# TZ10xx register map
File version: 0.1g
Registers are 32-bit, read-write, reset 0x0 unless marked. A register's access mark holds for its fields unless they carry their own. Offsets are from the block's base; [hi:lo] are bit positions; {n}, {i} and the like mark numbered series; 'fields as' and 'values as' point back to an identical list.

## pmulv (part 1 of 2)
Base 0x40000000
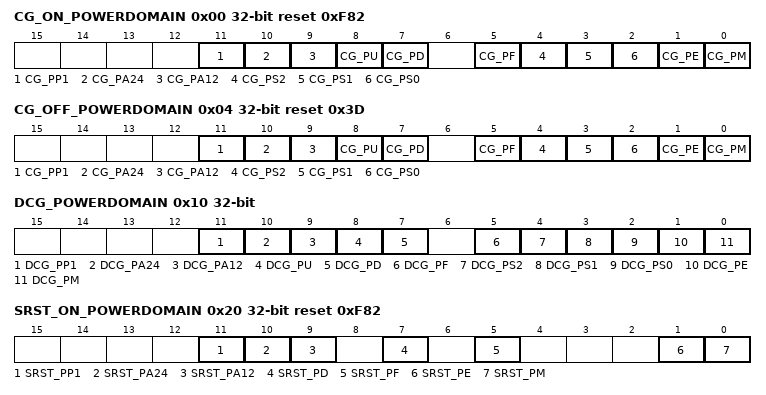
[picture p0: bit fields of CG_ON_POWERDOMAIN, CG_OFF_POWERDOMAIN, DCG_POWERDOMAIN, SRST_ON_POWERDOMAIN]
0x00 CG_ON_POWERDOMAIN reset 0xF82 — Clock gating ON (for each power supply domain) [Write]1: Clock stops. 0: Ignored [Read]1: Clock is stopped. 0: Clock is being supplied. * Writing also changes the values of associated individual CG registers. (Example) If writing is done to the CG_PD field, the values of the [CG_ON_PD] and [CG_OFF_PD] registers are also changed.
  [11] CG_PP1 — Batch control of clocks belonging to PP1
  [10] CG_PA24 — Batch control of clocks belonging to PA24
  [9] CG_PA12 — Batch control of clocks belonging to PA12
  [8] CG_PU — Batch control of clocks belonging to PU
  [7] CG_PD — Batch control of clocks belonging to PD
  [5] CG_PF — Batch control of clocks belonging to PF
  [4] CG_PS2 — Batch control of clocks belonging to PS2
  [3] CG_PS1 — Batch control of clocks belonging to PS1
  [2] CG_PS0 — Batch control of clocks belonging to PS0
  [1] CG_PE — Batch control of clocks belonging to PE
  [0] CG_PM — Batch control of clocks belonging to PM
0x04 CG_OFF_POWERDOMAIN reset 0x3D — Clock gating OFF (for each power supply domain) [Write]1: Clock is supplied. 0: Ignored [Read]1: Clock is being supplied. 0: Clock is stopped. * Writing also changes the values of associated individual CG registers. (Example) If writing is done to the CG_PD field, the values of the [CG_ON_PD] and [CG_OFF_PD] registers are also changed.
  fields as CG_ON_POWERDOMAIN
0x10 DCG_POWERDOMAIN — Dynamic clock gating (for each power supply domain) [Write]1: Dynamic clock gating enable. 0: Dynamic clock gating disable. [Read] A configured value can be checked. * Writing also changes values of associated individual DCG registers. (Example) If writing is done to the DCG_PD field, the [DCG_PD] register value is also changed.
  [11] DCG_PP1 — Batch control of clocks belonging to PP1
  [10] DCG_PA24 — Batch control of clocks belonging to PA24
  [9] DCG_PA12 — Batch control of clocks belonging to PA12
  [8] DCG_PU — Batch control of clocks belonging to PU
  [7] DCG_PD — Batch control of clocks belonging to PD
  [5] DCG_PF — Batch control of clocks belonging to PF
  [4] DCG_PS2 — Batch control of clocks belonging to PS2
  [3] DCG_PS1 — Batch control of clocks belonging to PS1
  [2] DCG_PS0 — Batch control of clocks belonging to PS0
  [1] DCG_PE — Batch control of clocks belonging to PE
  [0] DCG_PM — Batch control of clocks belonging to PM
0x20 SRST_ON_POWERDOMAIN reset 0xF82 — Soft reset ON (for each power supply domain) [Write]1: Reset assert. 0: Ignored. [Read]1: Reset assert in progress. 0: Reset deassert in progress * Writing also changes values of associated individual SRST registers. (Example) If writing is done to the SRST_PD field, the values of the [SRST_ON_PD] and [SRST_OFF_PD] registers are also changed.
  [11] SRST_PP1 — Batch control of resets belonging to PP1
  [10] SRST_PA24 — Batch control of resets belonging to PA24
  [9] SRST_PA12 — Batch control of resets belonging to PA12
  [7] SRST_PD — Batch control of resets belonging to PD
  [5] SRST_PF — Batch control of resets belonging to PF
  [1] SRST_PE — Batch control of resets belonging to PE
  [0] SRST_PM — Batch control of resets belonging to PM
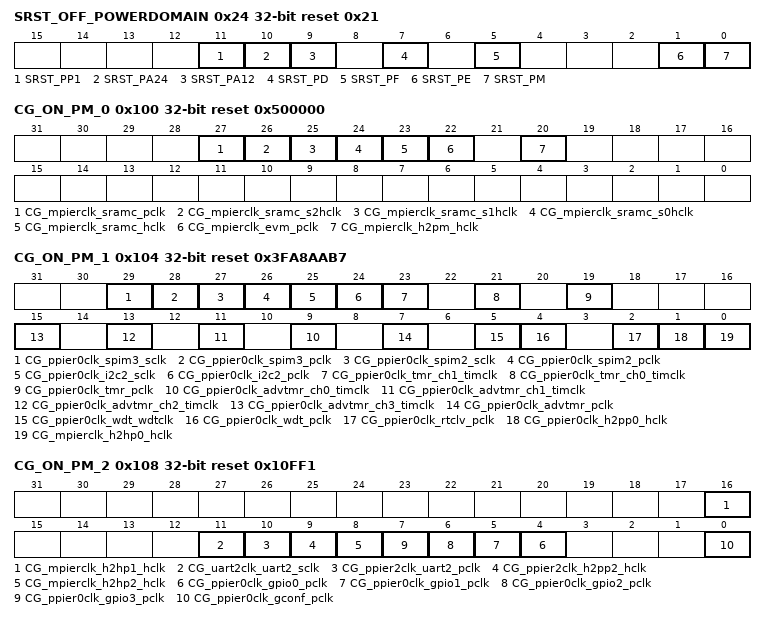
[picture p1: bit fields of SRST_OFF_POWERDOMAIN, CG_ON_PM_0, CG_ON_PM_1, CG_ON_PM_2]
0x24 SRST_OFF_POWERDOMAIN reset 0x21 — Soft reset OFF (for each power supply domain) [Write]1: Reset deassert. 0: Ignored. [Read]1: Reset deassert in progress. 0: Reset assert in progress * Writing also changes values of associated individual SRST registers. (Example) If writing is done to the SRST_PD field, the values of the [SRST_ON_PD] and [SRST_OFF_PD] registers are also changed.
  fields as SRST_ON_POWERDOMAIN
0x100 CG_ON_PM_0 reset 0x500000 — Clock gating ON (PM/PS0/PS1/PS2) [Write]1: Clock stops. 0: Ignored. [Read]1: Clock is stopped. 0: Clock is being supplied.
  [27] CG_mpierclk_sramc_pclk — SRAMC APB I/F clock * Also changed by writing to [CG_ON_POWERDOMAIN].CG_PM and [CG_OFF_POWERDOMAIN].CG_PM.
  [26] CG_mpierclk_sramc_s2hclk — SRAMC PS2 clock * Also changed by writing to [CG_ON_POWERDOMAIN].CG_PS2 and [CG_OFF_POWERDOMAIN].CG_PS2.
  [25] CG_mpierclk_sramc_s1hclk — SRAMC PS1 clock * Also changed by writing to [CG_ON_POWERDOMAIN].CG_PS1 and [CG_OFF_POWERDOMAIN].CG_PS1.
  [24] CG_mpierclk_sramc_s0hclk — SRAMC PS0 clock * Also changed by writing to [CG_ON_POWERDOMAIN].CG_PS0 and [CG_OFF_POWERDOMAIN].CG_PS0.
  [23] CG_mpierclk_sramc_hclk — SRAMC AHB I/F clock (T0/T1/T2) * Also changed by writing to [CG_ON_POWERDOMAIN].CG_PM and [CG_OFF_POWERDOMAIN].CG_PM.
  [22] CG_mpierclk_evm_pclk — EVM clock * Also changed by writing to [CG_ON_POWERDOMAIN].CG_PM and [CG_OFF_POWERDOMAIN].CG_PM.
  [20] CG_mpierclk_h2pm_hclk — H2APB clock * Also changed by writing to [CG_ON_POWERDOMAIN].CG_PM and [CG_OFF_POWERDOMAIN].CG_PM.
0x104 CG_ON_PM_1 reset 0x3FA8AAB7 — Clock gating ON (PM) [Write]1: Clock stops. 0: Ignored. [Read]1: Clock is stopped. 0: Clock is being supplied. * Also changed by writing to [CG_ON_POWERDOMAIN].CG_PM and [CG_OFF_POWERDOMAIN].CG_PM.
  [29] CG_ppier0clk_spim3_sclk — SPIM3 serial clock
  [28] CG_ppier0clk_spim3_pclk — SPIM3 APB I/F clock
  [27] CG_ppier0clk_spim2_sclk — SPIM2 serial clock
  [26] CG_ppier0clk_spim2_pclk — SPIM2 APB I/F clock
  [25] CG_ppier0clk_i2c2_sclk — I2C2 serial clock
  [24] CG_ppier0clk_i2c2_pclk — I2C2 APB I/F clock
  [23] CG_ppier0clk_tmr_ch1_timclk — TMR ch1 timer counter clock
  [21] CG_ppier0clk_tmr_ch0_timclk — TMR ch0 timer counter clock
  [19] CG_ppier0clk_tmr_pclk — TMR APB I/F clock
  [2n+9] CG_ppier0clk_advtmr_ch{n}_timclk (n=0..3) — ADVTMR ch{n} timer counter clock
  [7] CG_ppier0clk_advtmr_pclk — ADVTMR APB I/F clock
  [5] CG_ppier0clk_wdt_wdtclk — WDT timer counter clock
  [4] CG_ppier0clk_wdt_pclk — WDT APB I/F clock
  [2] CG_ppier0clk_rtclv_pclk — RTCLV APB I/F clock
  [1] CG_ppier0clk_h2pp0_hclk — H2APBP0 clock
  [0] CG_mpierclk_h2hp0_hclk — H2HSYNCDNP0 clock
0x108 CG_ON_PM_2 reset 0x10FF1 — Clock gating ON (PM) [Write]1: Clock stops. 0: Ignored. [Read]1: Clock is stopped. 0: Clock is being supplied. * Also changed by writing to [CG_ON_POWERDOMAIN].CG_PM and [CG_OFF_POWERDOMAIN].CG_PM.
  [16] CG_mpierclk_h2hp1_hclk — H2HSYNCDNP1 clock
  [11] CG_uart2clk_uart2_sclk — UART2 serial clock
  [10] CG_ppier2clk_uart2_pclk — UART2 APB I/F clock
  [9] CG_ppier2clk_h2pp2_hclk — H2APBP2 clock
  [8] CG_mpierclk_h2hp2_hclk — H2HSYNCDNP2 clock
  [n+4] CG_ppier0clk_gpio{n}_pclk (n=0..3) — GPIO{n} APB I/F clock
  [0] CG_ppier0clk_gconf_pclk — GCONF APB I/F clock
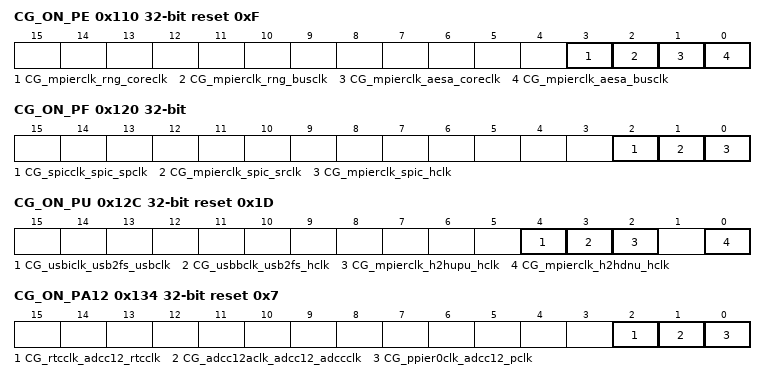
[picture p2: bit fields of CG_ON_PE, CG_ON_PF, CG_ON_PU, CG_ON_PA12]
0x110 CG_ON_PE reset 0xF — Clock gating ON (PE) [Write]1: Clock stops. 0: Ignored. [Read]1: Clock is stopped. 0: Clock is being supplied. * Also changed by writing to [CG_ON_POWERDOMAIN].CG_PE and [CG_OFF_POWERDOMAIN].CG_PE.
  [3] CG_mpierclk_rng_coreclk — RNG core clock
  [2] CG_mpierclk_rng_busclk — RNG APB I/F clock
  [1] CG_mpierclk_aesa_coreclk — AESA core clock
  [0] CG_mpierclk_aesa_busclk — AESA APB I/F clock
0x120 CG_ON_PF — Clock gating ON (PF) [Write]1: Clock stops. 0: Ignored. [Read]1: Clock is stopped. 0: Clock is being supplied. * Also changed by writing to [CG_ON_POWERDOMAIN].CG_PF and [CG_OFF_POWERDOMAIN].CG_PF.
  [2] CG_spicclk_spic_spclk — SPIC SPI clock
  [1] CG_mpierclk_spic_srclk — SPIC SRAM clock
  [0] CG_mpierclk_spic_hclk — SPIC AHB I/F clock
0x128 CG_ON_PD reset 0x1 — Clock gating ON (PD) [Write]1: Clock stops. 0: Ignored. [Read]1: Clock is stopped. 0: Clock is being supplied. * Also changed by writing to [CG_ON_POWERDOMAIN].CG_PD and [CG_OFF_POWERDOMAIN].CG_PD.
  [0] CG_mpierclk_sdmac_hclk — DMAC clock
0x12C CG_ON_PU reset 0x1D — Clock gating ON (PU) [Write]1: Clock stops. 0: Ignored. [Read]1: Clock is stopped. 0: Clock is being supplied. * Also changed by writing to [CG_ON_POWERDOMAIN].CG_PU and [CG_OFF_POWERDOMAIN].CG_PU.
  [4] CG_usbiclk_usb2fs_usbclk — USB USB clock
  [3] CG_usbbclk_usb2fs_hclk — USB AHB I/F clock
  [2] CG_mpierclk_h2hupu_hclk — H2HSYNCUPU clock
  [0] CG_mpierclk_h2hdnu_hclk — H2HSYNCDNU slave clock
0x134 CG_ON_PA12 reset 0x7 — Clock gating ON (PA12) [Write]1: Clock stops. 0: Ignored. [Read]1: Clock is stopped. 0: Clock is being supplied. * Also changed by writing to [CG_ON_POWERDOMAIN].CG_PA12 and [CG_OFF_POWERDOMAIN].CG_PA12.
  [2] CG_rtcclk_adcc12_rtcclk — ADC12 RTC clock
  [1] CG_adcc12aclk_adcc12_adccclk — ADC12 ADC clock
  [0] CG_ppier0clk_adcc12_pclk — ADC12 APB I/F clock
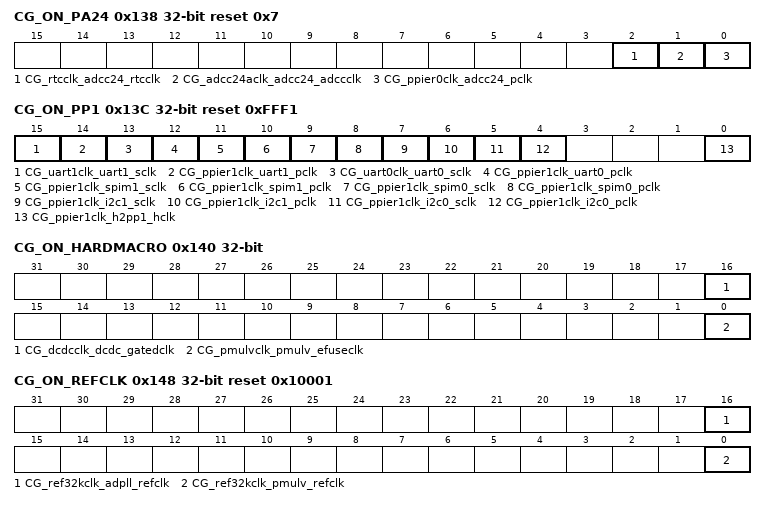
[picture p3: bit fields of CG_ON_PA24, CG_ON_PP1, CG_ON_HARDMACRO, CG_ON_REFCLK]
0x138 CG_ON_PA24 reset 0x7 — Clock gating ON (PA24) [Write]1: Clock stops. 0: Ignored. [Read]1: Clock is stopped. 0: Clock is being supplied. * Also changed by writing to [CG_ON_POWERDOMAIN].CG_PA24 and [CG_OFF_POWERDOMAIN].CG_PA24.
  [2] CG_rtcclk_adcc24_rtcclk — ADC24 RTC clock
  [1] CG_adcc24aclk_adcc24_adccclk — ADC24 ADC clock
  [0] CG_ppier0clk_adcc24_pclk — ADC24 APB I/F clock
0x13C CG_ON_PP1 reset 0xFFF1 — Clock gating ON (PP1) [Write]1: Clock stops. 0: Ignored. [Read]1: Clock is stopped. 0: Clock is being supplied. * Also changed by writing to [CG_ON_POWERDOMAIN].CG_PP1 and [CG_OFF_POWERDOMAIN].CG_PP1.
  [15] CG_uart1clk_uart1_sclk — UART1 serial clock
  [14] CG_ppier1clk_uart1_pclk — UART1 APB I/F clock
  [13] CG_uart0clk_uart0_sclk — UART0 serial clock
  [12] CG_ppier1clk_uart0_pclk — UART0 APB I/F clock
  [11] CG_ppier1clk_spim1_sclk — SPIM1 serial clock
  [10] CG_ppier1clk_spim1_pclk — SPIM1 APB I/F clock
  [9] CG_ppier1clk_spim0_sclk — SPIM0 serial clock
  [8] CG_ppier1clk_spim0_pclk — SPIM0 APB I/F clock
  [7] CG_ppier1clk_i2c1_sclk — I2C1 serial clock
  [6] CG_ppier1clk_i2c1_pclk — I2C1 APB I/F clock
  [5] CG_ppier1clk_i2c0_sclk — I2C0 serial clock
  [4] CG_ppier1clk_i2c0_pclk — I2C0 APB I/F clock
  [0] CG_ppier1clk_h2pp1_hclk — H2APBP1 clock
0x140 CG_ON_HARDMACRO — Clock gating ON (HARDMACRO) [Write]1: Clock stops. 0: Ignored. [Read]1: Clock is stopped. 0: Clock is being supplied.
  [16] CG_dcdcclk_dcdc_gatedclk — DCDC clock
  [0] CG_pmulvclk_pmulv_efuseclk — EFUSE clock
0x148 CG_ON_REFCLK reset 0x10001 — Clock gating ON (REFCLK) [Write]1: Clock stops. 0: Ignored. [Read]1: Clock is stopped. 0: Clock is being supplied.
  [16] CG_ref32kclk_adpll_refclk — ADPLL reference clock
  [0] CG_ref32kclk_pmulv_refclk — PMULV reference clock
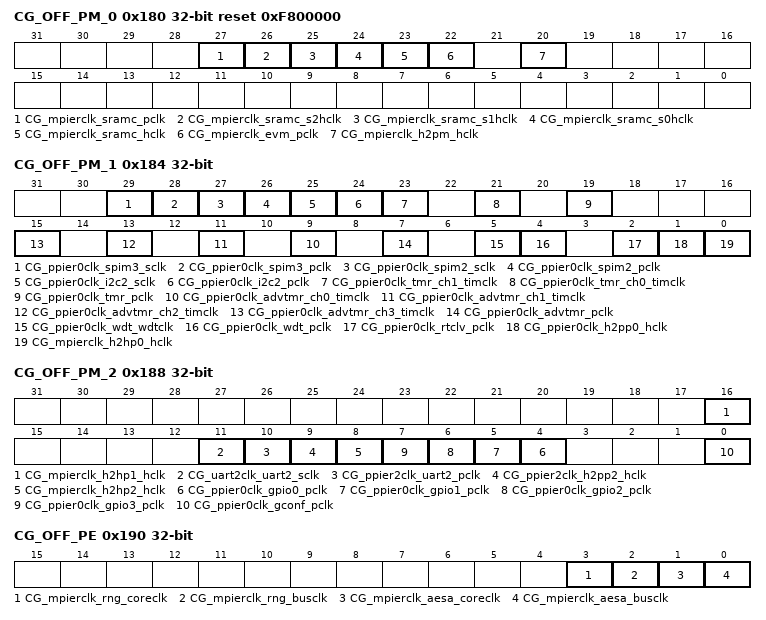
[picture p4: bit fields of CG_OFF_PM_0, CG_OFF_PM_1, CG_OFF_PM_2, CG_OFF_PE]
0x180 CG_OFF_PM_0 reset 0xF800000 — Clock gating OFF (PM/PS0/PS1/PS2) [Write]1: Clock is supplied. 0: Ignored. [Read]1: Clock is being supplied. 0: Clock is stopped.
  fields as CG_ON_PM_0
0x184 CG_OFF_PM_1 — Clock gating OFF (PM) [Write]1: Clock is supplied. 0: Ignored. [Read]1: Clock is being supplied. 0: Clock is stopped. * Also changed by writing to [CG_ON_POWERDOMAIN].CG_PM and [CG_OFF_POWERDOMAIN].CG_PM.
  fields as CG_ON_PM_1
0x188 CG_OFF_PM_2 — Clock gating OFF (PM) [Write]1: Clock is supplied. 0: Ignored. [Read]1: Clock is being supplied. 0: Clock is stopped. * Also changed by writing to [CG_ON_POWERDOMAIN].CG_PM and [CG_OFF_POWERDOMAIN].CG_PM.
  fields as CG_ON_PM_2
0x190 CG_OFF_PE — Clock gating OFF (PE) [Write]1: Clock is supplied. 0: Ignored. [Read]1: Clock is being supplied. 0: Clock is stopped. * Also changed by writing to [CG_ON_POWERDOMAIN].CG_PE and [CG_OFF_POWERDOMAIN].CG_PE.
  fields as CG_ON_PE
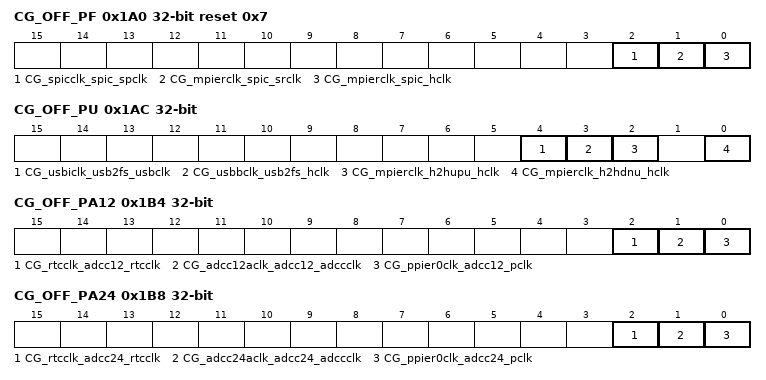
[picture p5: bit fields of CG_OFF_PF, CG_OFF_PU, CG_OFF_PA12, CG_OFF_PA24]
0x1A0 CG_OFF_PF reset 0x7 — Clock gating OFF (PF) [Write]1: Clock is supplied. 0: Ignored. [Read]1: Clock is being supplied. 0: Clock is stopped. * Also changed by writing to [CG_ON_POWERDOMAIN].CG_PF and [CG_OFF_POWERDOMAIN].CG_PF.
  fields as CG_ON_PF
0x1A8 CG_OFF_PD — Clock gating OFF (PD) [Write]1: Clock is supplied. 0: Ignored. [Read]1: Clock is being supplied. 0: Clock is stopped. * Also changed by writing to [CG_ON_POWERDOMAIN].CG_PD and [CG_OFF_POWERDOMAIN].CG_PD.
  [0] CG_mpierclk_sdmac_hclk — DMAC clock
0x1AC CG_OFF_PU — Clock gating OFF (PU) [Write]1: Clock is supplied. 0: Ignored. [Read]1: Clock is being supplied. 0: Clock is stopped. * Also changed by writing to [CG_ON_POWERDOMAIN].CG_PU and [CG_OFF_POWERDOMAIN].CG_PU.
  fields as CG_ON_PU
0x1B4 CG_OFF_PA12 — Clock gating OFF (PA12) [Write]1: Clock is supplied. 0: Ignored. [Read]1: Clock is being supplied. 0: Clock is stopped. * Also changed by writing to [CG_ON_POWERDOMAIN].CG_PA12 and [CG_OFF_POWERDOMAIN].CG_PA12.
  fields as CG_ON_PA12
0x1B8 CG_OFF_PA24 — Clock gating OFF (PA24) [Write]1: Clock is supplied. 0: Ignored. [Read]1: Clock is being supplied. 0: Clock is stopped. * Also changed by writing to [CG_ON_POWERDOMAIN].CG_PA24 and [CG_OFF_POWERDOMAIN].CG_PA24.
  fields as CG_ON_PA24
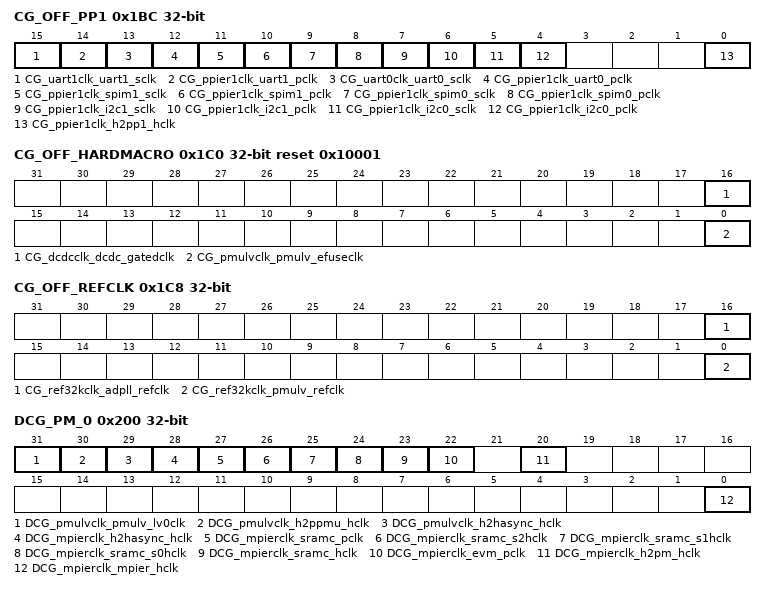
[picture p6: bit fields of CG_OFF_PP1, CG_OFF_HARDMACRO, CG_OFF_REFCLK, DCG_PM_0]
0x1BC CG_OFF_PP1 — Clock gating OFF (PP1) [Write]1: Clock is supplied. 0: Ignored. [Read]1: Clock is being supplied. 0: Clock is stopped. * Also changed by writing to [CG_ON_POWERDOMAIN].CG_PP1 and [CG_OFF_POWERDOMAIN].CG_PP1.
  fields as CG_ON_PP1
0x1C0 CG_OFF_HARDMACRO reset 0x10001 — Clock gating OFF (HARDMACRO) [Write]1: Clock is supplied. 0: Ignored. [Read]1: Clock is being supplied. 0: Clock is stopped.
  fields as CG_ON_HARDMACRO
0x1C8 CG_OFF_REFCLK — Clock gating OFF (HARDMACRO) [Write]1: Clock is supplied. 0: Ignored. [Read]1: Clock is being supplied. 0: Clock is stopped.
  fields as CG_ON_REFCLK
0x200 DCG_PM_0 — Dynamic clock gating (PM) [Write]1: Dynamic clock gating enable. 0: Dynamic clock gating disable [Read] A configured value can be checked.
  [31] DCG_pmulvclk_pmulv_lv0clk — PMULV clock * Also changed by writing to [DCG_POWERDOMAIN].DCG_PM.
  [30] DCG_pmulvclk_h2ppmu_hclk — H2APBPMU clock * Also changed by writing to [DCG_POWERDOMAIN].DCG_PM.
  [29] DCG_pmulvclk_h2hasync_hclk — H2HASYNC master clock * Also changed by writing to [DCG_POWERDOMAIN].DCG_PM.
  [28] DCG_mpierclk_h2hasync_hclk — H2HASYNC slave clock * Also changed by writing to [DCG_POWERDOMAIN].DCG_PM.
  [27] DCG_mpierclk_sramc_pclk — SRAMC APB I/F clock * Also changed by writing to [DCG_POWERDOMAIN].DCG_PM.
  [26] DCG_mpierclk_sramc_s2hclk — SRAMC PS2 clock * Also changed by writing to [DCG_POWERDOMAIN].DCG_PS2.
  [25] DCG_mpierclk_sramc_s1hclk — SRAMC PS1 clock * Also changed by writing to [DCG_POWERDOMAIN].DCG_PS1.
  [24] DCG_mpierclk_sramc_s0hclk — SRAMC PS0 clock * Also changed by writing to [DCG_POWERDOMAIN].DCG_PS0.
  [23] DCG_mpierclk_sramc_hclk — SRAMC AHB I/F clock * Also changed by writing to [DCG_POWERDOMAIN].DCG_PM.
  [22] DCG_mpierclk_evm_pclk — EVM clock * Also changed by writing to [DCG_POWERDOMAIN].DCG_PM.
  [20] DCG_mpierclk_h2pm_hclk — H2APBM clock * Also changed by writing to [DCG_POWERDOMAIN].DCG_PM.
  [0] DCG_mpierclk_mpier_hclk — MPIER clock * Also changed by writing to [DCG_POWERDOMAIN].DCG_PM.
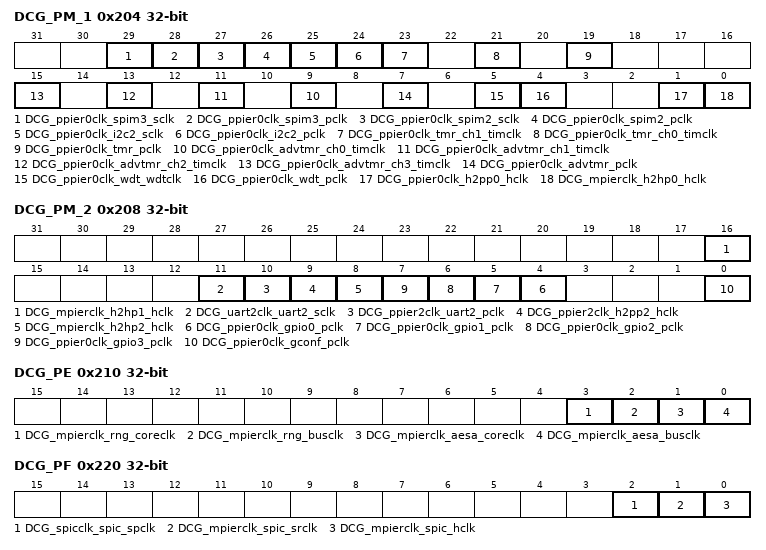
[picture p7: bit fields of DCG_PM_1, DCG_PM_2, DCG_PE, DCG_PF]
0x204 DCG_PM_1 — Dynamic clock gating (PM) [Write]1: Dynamic clock gating enable. 0: Dynamic clock gating disable [Read] A configured value can be checked. * Also changed by writing to [DCG_POWERDOMAIN].DCG_PM.
  [29] DCG_ppier0clk_spim3_sclk — SPIM3 serial clock
  [28] DCG_ppier0clk_spim3_pclk — SPIM3 APB I/F clock
  [27] DCG_ppier0clk_spim2_sclk — SPIM2 serial clock
  [26] DCG_ppier0clk_spim2_pclk — SPIM2 APB I/F clock
  [25] DCG_ppier0clk_i2c2_sclk — I2C2 serial clock
  [24] DCG_ppier0clk_i2c2_pclk — I2C2 APB I/F clock
  [23] DCG_ppier0clk_tmr_ch1_timclk — TMR ch1 timer counter clock
  [21] DCG_ppier0clk_tmr_ch0_timclk — TMR ch0 timer counter clock
  [19] DCG_ppier0clk_tmr_pclk — TMR APB I/F clock
  [2n+9] DCG_ppier0clk_advtmr_ch{n}_timclk (n=0..3) — ADVTMR ch{n} timer counter clock
  [7] DCG_ppier0clk_advtmr_pclk — ADVTMR APB I/F clock
  [5] DCG_ppier0clk_wdt_wdtclk — WDT timer counter clock
  [4] DCG_ppier0clk_wdt_pclk — WDT APB I/F clock
  [1] DCG_ppier0clk_h2pp0_hclk — H2APBP0 clock
  [0] DCG_mpierclk_h2hp0_hclk — H2HSYNCDNP0 clock
0x208 DCG_PM_2 — Dynamic clock gating (PM) [Write]1: Dynamic clock gating enable. 0: Dynamic clock gating disable [Read] A configured value can be checked. * Also changed by writing to [DCG_POWERDOMAIN].DCG_PM.
  [16] DCG_mpierclk_h2hp1_hclk — H2HSYNCDNP1 clock
  [11] DCG_uart2clk_uart2_sclk — UART2 serial clock
  [10] DCG_ppier2clk_uart2_pclk — UART2 APB I/F clock
  [9] DCG_ppier2clk_h2pp2_hclk — H2APBP2 clock
  [8] DCG_mpierclk_h2hp2_hclk — H2HSYNCDNP2 clock
  [n+4] DCG_ppier0clk_gpio{n}_pclk (n=0..3) — GPIO{n} APB I/F clock
  [0] DCG_ppier0clk_gconf_pclk — GCONF APB I/F clock
0x210 DCG_PE — Dynamic clock gating (PE) [Write]1: Dynamic clock gating enable. 0: Dynamic clock gating disable [Read] A configured value can be checked. * Also changed by writing to [DCG_POWERDOMAIN].DCG_PE.
  [3] DCG_mpierclk_rng_coreclk — RNG core clock
  [2] DCG_mpierclk_rng_busclk — RNG APB I/F clock
  [1] DCG_mpierclk_aesa_coreclk — AESA core clock
  [0] DCG_mpierclk_aesa_busclk — AESA APB I/F clock
0x220 DCG_PF — Dynamic clock gating (PF) [Write]1: Dynamic clock gating enable. 0: Dynamic clock gating disable [Read] A configured value can be checked. * Also changed by writing to [DCG_POWERDOMAIN].DCG_PF.
  [2] DCG_spicclk_spic_spclk — SPIC SPI clock
  [1] DCG_mpierclk_spic_srclk — SPIC SRAM clock
  [0] DCG_mpierclk_spic_hclk — SPIC AHB I/F clock
0x228 DCG_PD — Dynamic clock gating (PD) [Write]1: Dynamic clock gating enable. 0: Dynamic clock gating disable [Read] A configured value can be checked. * Also changed by writing to [DCG_POWERDOMAIN].DCG_PD.
  [0] DCG_mpierclk_sdmac_hclk — DMAC clock
0x22C DCG_PU — Dynamic clock gating (PU) [Write]1: Dynamic clock gating enable. 0: Dynamic clock gating disable [Read] A configured value can be checked. * Also changed by writing to [DCG_POWERDOMAIN].DCG_PU.
  [0] DCG_mpierclk_h2hdnu_hclk — H2HSYNCDNU slave clock
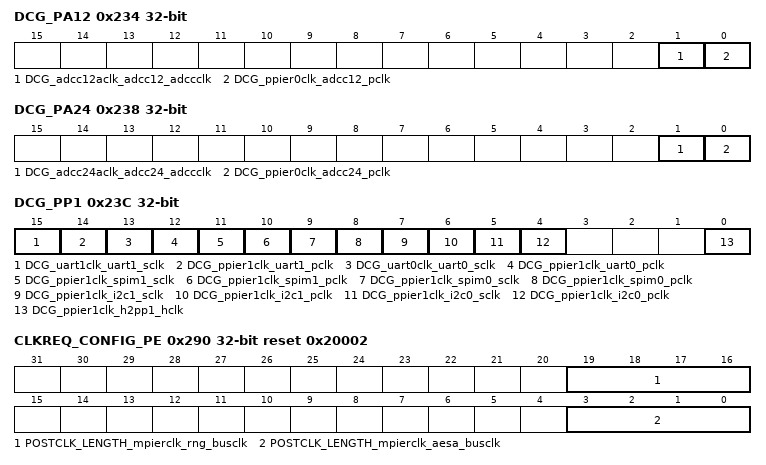
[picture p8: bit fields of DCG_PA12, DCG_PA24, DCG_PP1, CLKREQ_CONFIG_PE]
0x234 DCG_PA12 — Dynamic clock gating (PA12) [Write]1: Dynamic clock gating enable. 0: Dynamic clock gating disable [Read] A configured value can be checked. * Also changed by writing to [DCG_POWERDOMAIN].DCG_PA12.
  [1] DCG_adcc12aclk_adcc12_adccclk — ADC12 ADC clock
  [0] DCG_ppier0clk_adcc12_pclk — ADC12 APB I/F clock
0x238 DCG_PA24 — Dynamic clock gating (PA24) [Write]1: Dynamic clock gating enable. 0: Dynamic clock gating disable [Read] A configured value can be checked. * Also changed by writing to [DCG_POWERDOMAIN].DCG_PA24.
  [1] DCG_adcc24aclk_adcc24_adccclk — ADC24 ADC clock
  [0] DCG_ppier0clk_adcc24_pclk — ADC24 APB I/F clock
0x23C DCG_PP1 — Dynamic clock gating (PP1) [Write]1: Dynamic clock gating enable. 0: Dynamic clock gating disable [Read] A configured value can be checked. * Also changed by writing to [DCG_POWERDOMAIN].DCG_PP1.
  [15] DCG_uart1clk_uart1_sclk — UART1 serial clock
  [14] DCG_ppier1clk_uart1_pclk — UART1 APB I/F clock
  [13] DCG_uart0clk_uart0_sclk — UART0 serial clock
  [12] DCG_ppier1clk_uart0_pclk — UART0 APB I/F clock
  [11] DCG_ppier1clk_spim1_sclk — SPIM1 serial clock
  [10] DCG_ppier1clk_spim1_pclk — SPIM1 APB I/F clock
  [9] DCG_ppier1clk_spim0_sclk — SPIM0 serial clock
  [8] DCG_ppier1clk_spim0_pclk — SPIM0 APB I/F clock
  [7] DCG_ppier1clk_i2c1_sclk — I2C1 serial clock
  [6] DCG_ppier1clk_i2c1_pclk — I2C1 APB I/F clock
  [5] DCG_ppier1clk_i2c0_sclk — I2C0 serial clock
  [4] DCG_ppier1clk_i2c0_pclk — I2C0 APB I/F clock
  [0] DCG_ppier1clk_h2pp1_hclk — H2APBP1 clock
0x290 CLKREQ_CONFIG_PE reset 0x20002 — Sets the clock supply period extension after bus transaction. 0x0: 0cycle (no extension) 0x1: 1cycle 0x2: 2cycle 0x3: 3cycle 0x4: 4cycle 0x5: 5cycle 0x6: 6cycle 0x7: 7cycle 0x8: 8cycle 0x9: 9cycle 0xA: 10cycle 0xB: 11cycle 0xC: 12cycle 0xD: 13cycle 0xE: 14cycle 0xF: 15cycle
  [19:16] POSTCLK_LENGTH_mpierclk_rng_busclk — RNG APB I/F clock
  [3:0] POSTCLK_LENGTH_mpierclk_aesa_busclk — AESA APB I/F clock
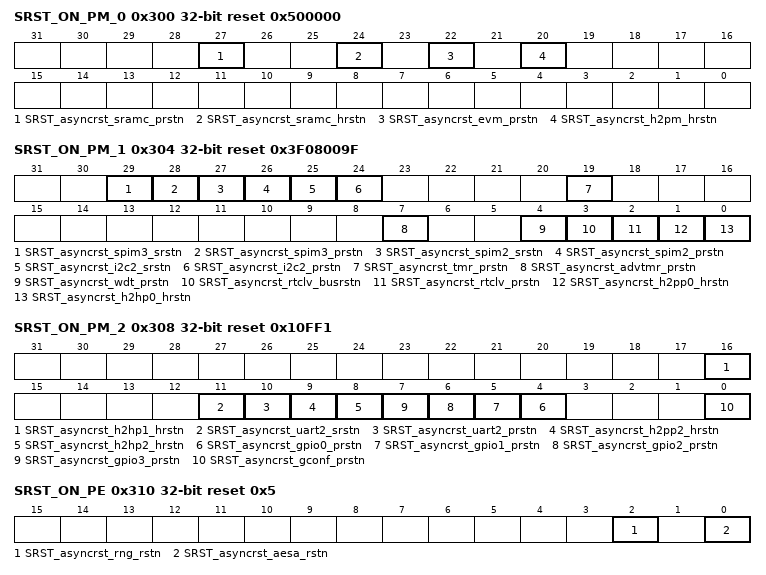
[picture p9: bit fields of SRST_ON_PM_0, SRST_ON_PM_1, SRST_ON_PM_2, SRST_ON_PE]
0x300 SRST_ON_PM_0 reset 0x500000 — Soft reset ON (PM) [Write]1: Reset assert. 0: Ignored. [Read]1: Reset assert in progress. 0: Reset deassert in progress * Also changed by writing to [SRST_ON_POWERDOMAIN].CG_PM and [SRST_OFF_POWERDOMAIN].CG_PM.
  [27] SRST_asyncrst_sramc_prstn — SRAMC APB I/F reset
  [24] SRST_asyncrst_sramc_hrstn — SRAMC AHB I/F reset
  [22] SRST_asyncrst_evm_prstn — EVM reset
  [20] SRST_asyncrst_h2pm_hrstn — H2APBM reset
0x304 SRST_ON_PM_1 reset 0x3F08009F — Soft reset ON (PM) [Write]1: Reset assert. 0: Ignored. [Read]1: Reset assert in progress. 0: Reset deassert in progress * Also changed by writing to [SRST_ON_POWERDOMAIN].CG_PM and [SRST_OFF_POWERDOMAIN].CG_PM.
  [29] SRST_asyncrst_spim3_srstn — SPIM3 serial reset
  [28] SRST_asyncrst_spim3_prstn — SPIM3 APB I/F reset
  [27] SRST_asyncrst_spim2_srstn — SPIM2 serial reset
  [26] SRST_asyncrst_spim2_prstn — SPIM2 APB I/F reset
  [25] SRST_asyncrst_i2c2_srstn — I2C2 serial reset
  [24] SRST_asyncrst_i2c2_prstn — I2C2 APB I/F reset
  [19] SRST_asyncrst_tmr_prstn — TMR reset
  [7] SRST_asyncrst_advtmr_prstn — ADVTMR reset
  [4] SRST_asyncrst_wdt_prstn — WDT reset.
  [3] SRST_asyncrst_rtclv_busrstn — RTCLV timer reset
  [2] SRST_asyncrst_rtclv_prstn — RTCLV APB I/F reset
  [1] SRST_asyncrst_h2pp0_hrstn — H2APBP0 reset
  [0] SRST_asyncrst_h2hp0_hrstn — H2HSYNCDNP0 reset
0x308 SRST_ON_PM_2 reset 0x10FF1 — Soft reset ON (PM) [Write]1: Reset assert. 0: Ignored. [Read]1: Reset assert in progress. 0: Reset deassert in progress * Also changed by writing to [SRST_ON_POWERDOMAIN].CG_PM and [SRST_OFF_POWERDOMAIN].CG_PM.
  [16] SRST_asyncrst_h2hp1_hrstn — H2HSYNCDNP1 reset
  [11] SRST_asyncrst_uart2_srstn — UART2 serial reset.
  [10] SRST_asyncrst_uart2_prstn — UART2 APB I/F reset
  [9] SRST_asyncrst_h2pp2_hrstn — H2APBP2 reset
  [8] SRST_asyncrst_h2hp2_hrstn — H2HSYNCDNP2 reset
  [n+4] SRST_asyncrst_gpio{n}_prstn (n=0..3) — GPIO{n} APB I/F reset
  [0] SRST_asyncrst_gconf_prstn — GCONF APB I/F reset
0x310 SRST_ON_PE reset 0x5 — Soft reset ON (PE) [Write]1: Reset assert. 0: Ignored. [Read]1: Reset assert in progress. 0: Reset deassert in progress * Also changed by writing to [SRST_ON_POWERDOMAIN].CG_PE and [SRST_OFF_POWERDOMAIN].CG_PE.
  [2] SRST_asyncrst_rng_rstn — RNG reset
  [0] SRST_asyncrst_aesa_rstn — AESA reset
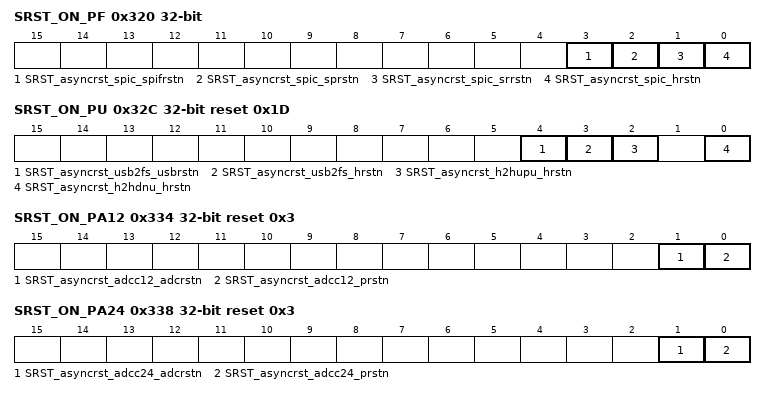
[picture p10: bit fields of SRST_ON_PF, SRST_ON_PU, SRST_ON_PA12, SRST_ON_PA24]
0x320 SRST_ON_PF — Soft reset ON (PF) [Write]1: Reset assert. 0: Ignored. [Read]1: Reset assert in progress. 0: Reset deassert in progress * Also changed by writing to [SRST_ON_POWERDOMAIN].CG_PF and [SRST_OFF_POWERDOMAIN].CG_PF.
  [3] SRST_asyncrst_spic_spifrstn — SPIC SPIF reset
  [2] SRST_asyncrst_spic_sprstn — SPIC SPI reset
  [1] SRST_asyncrst_spic_srrstn — SPIC SRAM reset
  [0] SRST_asyncrst_spic_hrstn — SPIC AHB I/F reset
0x328 SRST_ON_PD reset 0x1 — Soft reset ON (PD) [Write]1: Reset assert. 0: Ignored. [Read]1: Reset assert in progress. 0: Reset deassert in progress * Also changed by writing to [SRST_ON_POWERDOMAIN].CG_PD and [SRST_OFF_POWERDOMAIN].CG_PD.
  [0] SRST_asyncrst_sdmac_hrstn — DMAC reset
0x32C SRST_ON_PU reset 0x1D — Soft reset ON (PU) [Write]1: Reset assert. 0: Ignored. [Read]1: Reset assert in progress. 0: Reset deassert in progress * Also changed by writing to [SRST_ON_POWERDOMAIN].CG_PU and [SRST_OFF_POWERDOMAIN].CG_PU.
  [4] SRST_asyncrst_usb2fs_usbrstn — USB USB reset
  [3] SRST_asyncrst_usb2fs_hrstn — USB AHB I/F reset
  [2] SRST_asyncrst_h2hupu_hrstn — H2HSYNCUPU reset
  [0] SRST_asyncrst_h2hdnu_hrstn — H2HSYNCDNU reset
0x334 SRST_ON_PA12 reset 0x3 — Soft reset ON (PM) [Write]1: Reset assert. 0: Ignored. [Read]1: Reset assert in progress. 0: Reset deassert in progress * Also changed by writing to [SRST_ON_POWERDOMAIN].CG_PM and [SRST_OFF_POWERDOMAIN].CG_PM.
  [1] SRST_asyncrst_adcc12_adcrstn — ADCC12 ADC reset
  [0] SRST_asyncrst_adcc12_prstn — ADCC12 APB I/F reset
0x338 SRST_ON_PA24 reset 0x3 — Soft reset ON (PA24) [Write]1: Reset assert. 0: Ignored. [Read]1: Reset assert in progress. 0: Reset deassert in progress * Also changed by writing to [SRST_ON_POWERDOMAIN].CG_PA24 and [SRST_OFF_POWERDOMAIN].CG_PA24.
  [1] SRST_asyncrst_adcc24_adcrstn — ADCC24 ADC reset
  [0] SRST_asyncrst_adcc24_prstn — ADCC24 APB I/F reset
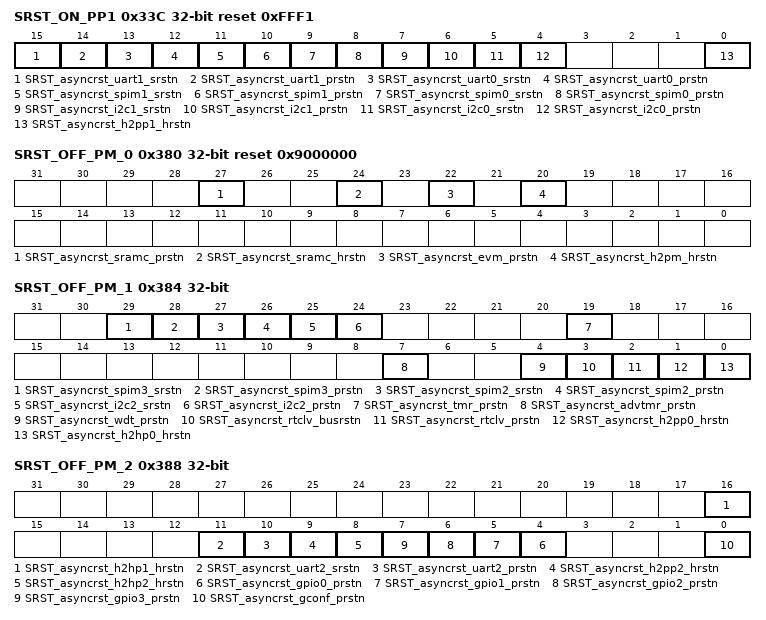
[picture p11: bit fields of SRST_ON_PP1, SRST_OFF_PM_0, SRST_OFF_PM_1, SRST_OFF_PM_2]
0x33C SRST_ON_PP1 reset 0xFFF1 — Soft reset ON (PP1) [Write]1: Reset assert. 0: Ignored. [Read]1: Reset assert in progress. 0: Reset deassert in progress * Also changed by writing to [SRST_ON_POWERDOMAIN].CG_PP1 and [SRST_OFF_POWERDOMAIN].CG_PP1.
  [15] SRST_asyncrst_uart1_srstn — UART1 serial reset.
  [14] SRST_asyncrst_uart1_prstn — UART1 APB I/F reset
  [13] SRST_asyncrst_uart0_srstn — UART0 serial reset.
  [12] SRST_asyncrst_uart0_prstn — UART0 APB I/F reset
  [11] SRST_asyncrst_spim1_srstn — SPIM1 serial reset
  [10] SRST_asyncrst_spim1_prstn — SPIM1 APB I/F reset
  [9] SRST_asyncrst_spim0_srstn — SPIM0 serial reset
  [8] SRST_asyncrst_spim0_prstn — SPIM0 APB I/F reset
  [7] SRST_asyncrst_i2c1_srstn — I2C1 serial reset
  [6] SRST_asyncrst_i2c1_prstn — I2C1 APB I/F reset
  [5] SRST_asyncrst_i2c0_srstn — I2C0 serial reset
  [4] SRST_asyncrst_i2c0_prstn — I2C0 APB I/F reset
  [0] SRST_asyncrst_h2pp1_hrstn — H2APBP1 reset
0x380 SRST_OFF_PM_0 reset 0x9000000 — Soft reset OFF (PM) [Write]1: Reset deassert. 0: Ignored. [Read]1: Reset deassert in progress. 0: Reset assert in progress * Also changed by writing to [SRST_ON_POWERDOMAIN].CG_PM and [SRST_OFF_POWERDOMAIN].CG_PM.
  fields as SRST_ON_PM_0
0x384 SRST_OFF_PM_1 — Soft reset OFF (PM) [Write]1: Reset deassert. 0: Ignored. [Read]1: Reset deassert in progress. 0: Reset assert in progress * Also changed by writing to [SRST_ON_POWERDOMAIN].CG_PM and [SRST_OFF_POWERDOMAIN].CG_PM.
  fields as SRST_ON_PM_1
0x388 SRST_OFF_PM_2 — Soft reset OFF (PM) [Write]1: Reset deassert. 0: Ignored. [Read]1: Reset deassert in progress. 0: Reset assert in progress * Also changed by writing to [SRST_ON_POWERDOMAIN].CG_PM and [SRST_OFF_POWERDOMAIN].CG_PM.
  fields as SRST_ON_PM_2
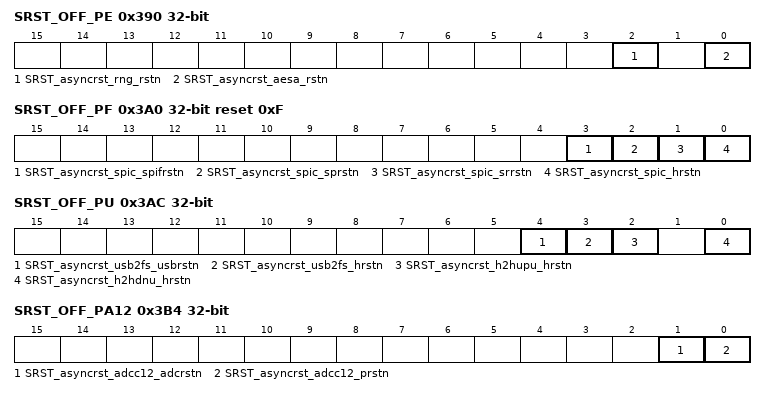
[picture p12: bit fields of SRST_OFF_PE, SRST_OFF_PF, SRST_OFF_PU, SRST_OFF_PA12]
0x390 SRST_OFF_PE — Soft reset OFF (PE) [Write]1: Reset deassert. 0: Ignored. [Read]1: Reset deassert in progress. 0: Reset assert in progress * Also changed by writing to [SRST_ON_POWERDOMAIN].CG_PE and [SRST_OFF_POWERDOMAIN].CG_PE.
  fields as SRST_ON_PE
0x3A0 SRST_OFF_PF reset 0xF — Soft reset OFF (PF) [Write]1: Reset deassert. 0: Ignored. [Read]1: Reset deassert in progress. 0: Reset assert in progress * Also changed by writing to [SRST_ON_POWERDOMAIN].CG_PF and [SRST_OFF_POWERDOMAIN].CG_PF.
  fields as SRST_ON_PF
0x3A8 SRST_OFF_PD — Soft reset OFF (PD) [Write]1: Reset deassert. 0: Ignored. [Read]1: Reset deassert in progress. 0: Reset assert in progress * Also changed by writing to [SRST_ON_POWERDOMAIN].CG_PD and [SRST_OFF_POWERDOMAIN].CG_PD.
  [0] SRST_asyncrst_sdmac_hrstn — DMAC reset
0x3AC SRST_OFF_PU — Soft reset OFF (PU) [Write]1: Reset deassert. 0: Ignored. [Read]1: Reset deassert in progress. 0: Reset assert in progress * Also changed by writing to [SRST_ON_POWERDOMAIN].CG_PU and [SRST_OFF_POWERDOMAIN].CG_PU.
  fields as SRST_ON_PU
0x3B4 SRST_OFF_PA12 — Soft reset OFF (PA12) [Write]1: Reset deassert. 0: Ignored. [Read]1: Reset deassert in progress. 0: Reset assert in progress * Also changed by writing to [SRST_ON_POWERDOMAIN].CG_PA12 and [SRST_OFF_POWERDOMAIN].CG_PA12.
  fields as SRST_ON_PA12
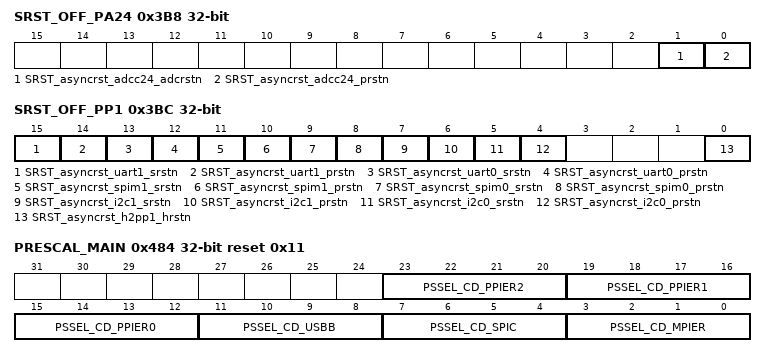
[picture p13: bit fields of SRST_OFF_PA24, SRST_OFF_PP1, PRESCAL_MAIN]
0x3B8 SRST_OFF_PA24 — Soft reset OFF (PA24) [Write]1: Reset deassert. 0: Ignored. [Read]1: Reset deassert in progress. 0: Reset assert in progress * Also changed by writing to [SRST_ON_POWERDOMAIN].CG_PA24 and [SRST_OFF_POWERDOMAIN].CG_PA24.
  fields as SRST_ON_PA24
0x3BC SRST_OFF_PP1 — Soft reset OFF (PP1) [Write]1: Reset deassert. 0: Ignored. [Read]1: Reset deassert in progress. 0: Reset assert in progress * Also changed by writing to [SRST_ON_POWERDOMAIN].CG_PP1 and [SRST_OFF_POWERDOMAIN].CG_PP1.
  fields as SRST_ON_PP1
0x404 CSM_MAIN — Clock source setting (CD_MPIER/CD_PPIER0/CD_PPIER1/CD_PPIER2/CD_SPIC/CD_USBB)
  [2:0] CSMSEL_MAIN — 0b000: SIOSC4M 0b001: OSC12M 0b010: PLL 0b011: ADPLL 0b100: OSC32K/SIOSC32K 0b101: ignored 0b110: ignored 0b111: ignored * OSC32K and SIOSC32K are switched with [CSM_RTC]. * The initial value is determined with a value stored in EFUSE.
0x408 CSM_CPUTRC — Clock source setting (CD_CPUTRC)
  [0] CSMSEL_CPUTRC — 0b0:SIOSC4M 0b1:OSC12M
0x40C CSM_CPUST — Clock source setting (CD_CPUST)
  [2:0] CSMSEL_CPUST — 0b000: SIOSC4M 0b001: OSC12M 0b010: ignored 0b011: ignored 0b100: OSC32K/SIOSC32K 0b101: ignored 0b110: ignored 0b111: ignored * OSC32K and SIOSC32K are switched with [CSM_RTC].
0x410 CSM_USBI — Clock source setting (CD USBI)
  [0] CSMSEL_USBI — 0b0:PLL 0b1:ADPLL
{0x414+4i} CSM_UART{i} (i=0..2) — Clock source setting (CD UART{i})
  [2:0] CSMSEL_UART{i} — 0b000: SIOSC4M 0b001: OSC12M 0b010: PLL 0b011: ADPLL 0b100: OSC32K/SIOSC32K 0b101: ignored 0b110: ignored 0b111: ignored * OSC32K and SIOSC32K are switched with [CSM_RTC].
0x420 CSM_ADCC12A — Clock source setting (CD ADCC12)
  [2:0] CSMSEL_ADCC12A — 0b000: SIOSC4M 0b001: OSC12M 0b010: PLL 0b011: ADPLL 0b100: ignored 0b101: 1/3 frequency division of OSC12M 0b110: 1/3 frequency division of PLL 0b111: 1/9 frequency division of PLL * If the value is 0b101-111, set 0x1 to [PRESCAL_ADCC12A].
0x424 CSM_ADCC24A — Clock source setting (CD ADCC24)
  [2:0] CSMSEL_ADCC24A — 0b000: SIOSC4M 0b001: OSC12M 0b010: PLL 0b011: ADPLL 0b100: ignored 0b101: 1/3 frequency division of OSC12M 0b110: ignored 0b111: 1/9 frequency division of PLL * If the value is 0b101 or 0b111, set 0x1 to [PRESCAL_ADCC24A].
0x484 PRESCAL_MAIN reset 0x11 — Prescaler setting (CD_MPIER/CD_PPIER0/CD_PPIER1/CD_PPIER2/CD_SPIC/CD_USBB) 0x0: Stop 0x1: 1/1 frequency division 0x2: 1/2 frequency division 0x3: 1/3 frequency division 0x4: 1/4 frequency division 0x5: 1/5 frequency division 0x6: 1/6 frequency division 0x7: 1/7 frequency division 0x8: 1/8 frequency division 0x9: 1/9 frequency division 0xA: 1/10 frequency division 0xB: 1/12 frequency division 0xC: 1/18 frequency division 0xD: 1/24 frequency division 0xE: 1/36 frequency division 0xF: 1/48 frequency division
  [23:20] PSSEL_CD_PPIER2 — CD_PPIER2 * The frequency is divided for the clock selected with CSM_MAIN. * Frequency=fCSM_MAIN/(DIVPSSEL_CD_MPIER * DIVPSSEL_CD_PPIER2)
  [19:16] PSSEL_CD_PPIER1 — CD_PPIER1 * The frequency is divided for the clock selected with CSM_MAIN. * Frequency=fCSM_MAIN/(DIVPSSEL_CD_MPIER * DIVPSSEL_CD_PPIER1)
  [15:12] PSSEL_CD_PPIER0 — CD_PPIER0 * The frequency is divided for the clock selected with CSM_MAIN. * Frequency=fCSM_MAIN/(DIVPSSEL_CD_MPIER * DIVPSSEL_CD_PPIER0)
  [11:8] PSSEL_CD_USBB — CD_USBB * The frequency is divided for the clock selected with CSM_MAIN. * Frequency=fCSM_MAIN/(DIVPSSEL_CD_MPIER * DIVPSSEL_CD_USBB)
  [7:4] PSSEL_CD_SPIC — CD_SPIC * The frequency is divided for the clock selected with CSM_MAIN. * Frequency=fCSM_MAIN/DIVPSSEL_CD_SPIC
  [3:0] PSSEL_CD_MPIER — CD_MPIER * 0x0: Setting prohibited
0x48C PRESCAL_CPUST reset 0x1 — Prescaler setting (CD_CPUST) 0x0: Stop 0x1: 1/1 frequency division 0x2: 1/2 frequency division 0x3: 1/3 frequency division 0x4: 1/4 frequency division 0x5: 1/5 frequency division 0x6: 1/6 frequency division 0x7: 1/7 frequency division 0x8: 1/8 frequency division 0x9: 1/9 frequency division 0xA: 1/10 frequency division 0xB: 1/12 frequency division 0xC: 1/18 frequency division 0xD: 1/24 frequency division 0xE: 1/36 frequency division 0xF: 1/48 frequency division
  [3:0] PSSEL_CD_CPUST — CD_CPUST
0x490 PRESCAL_USBI — Prescaler setting (CD_USBI) 0x0: Stop 0x1: 1/1 frequency division 0x2: 1/2 frequency division 0x3: 1/3 frequency division 0x4: 1/4 frequency division 0x5: 1/5 frequency division 0x6: 1/6 frequency division 0x7: 1/7 frequency division 0x8: 1/8 frequency division 0x9: 1/9 frequency division 0xA: 1/10 frequency division 0xB: 1/12 frequency division 0xC: 1/18 frequency division 0xD: 1/24 frequency division 0xE: 1/36 frequency division 0xF: 1/48 frequency division
  [3:0] PSSEL_CD_USBI — CD_USBI
